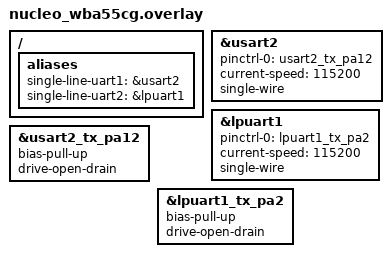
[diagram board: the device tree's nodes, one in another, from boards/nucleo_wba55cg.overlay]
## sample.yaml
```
sample:
  name: STM32 Single Wire UART sample
tests:
  sample.boards.stm32.uart.single_wire:
    platform_allow:
      - stm32f3_disco
      - nucleo_wba55cg
    tags:
      - drivers
      - uart
    harness: console
    harness_config:
      fixture: single_line_uart_loopback
      type: one_line
      regex:
        - "Received c"
```

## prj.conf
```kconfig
# SPDX-FileCopyrightText: Copyright The Zephyr Project Contributors
# SPDX-License-Identifier: Apache-2.0

# Nothing needed here
```

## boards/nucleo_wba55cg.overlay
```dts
/*
 * SPDX-License-Identifier: Apache-2.0
 *
 * Copyright (c) 2025 STMicroelectronics
 */

&usart2 {
	pinctrl-0 = <&usart2_tx_pa12>;
	current-speed = <115200>;
	single-wire;
	status = "okay";
};

&lpuart1 {
	pinctrl-0 = <&lpuart1_tx_pa2>;
	current-speed = <115200>;
	single-wire;
	status = "okay";
};

&usart2_tx_pa12 {
	bias-pull-up;
	drive-open-drain;
};

&lpuart1_tx_pa2 {
	bias-pull-up;
	drive-open-drain;
};

/ {
	aliases {
		single-line-uart1 = &usart2;
		single-line-uart2 = &lpuart1;
	};
};
```

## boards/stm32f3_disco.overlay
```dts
/*
 * Copyright (c) 2021 Jonathan Hahn
 *
 * SPDX-License-Identifier: Apache-2.0
 */

/ {
	aliases {
		single-line-uart1 = &usart2;
		single-line-uart2 = &uart4;
	};
};

&usart2 {
	pinctrl-0 = <&usart2_tx_pa2>;
	single-wire;
};

&uart4 {
	pinctrl-0 = <&uart4_tx_pc10>;
	single-wire;
};
```

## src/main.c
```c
/*
 * Copyright (c) 2021 Jonathan Hahn
 *
 * SPDX-License-Identifier: Apache-2.0
 */

#include <zephyr/kernel.h>
#include <zephyr/device.h>
#include <zephyr/devicetree.h>
#include <zephyr/drivers/uart.h>

#define UART_NODE1 DT_ALIAS(single_line_uart1)
#define UART_NODE2 DT_ALIAS(single_line_uart2)

const struct device *const sl_uart1 = DEVICE_DT_GET(UART_NODE1);
const struct device *const sl_uart2 = DEVICE_DT_GET(UART_NODE2);

int main(void)
{
	unsigned char recv;

	if (!device_is_ready(sl_uart1) || !device_is_ready(sl_uart2)) {
		printk("uart devices not ready\n");
		return 0;
	}

	while (true) {

		uart_poll_out(sl_uart1, 'c');

		/* give the uarts some time to get the data through */
		k_sleep(K_MSEC(50));

		int ret = uart_poll_in(sl_uart2, &recv);

		if (ret < 0) {
			printk("Receiving failed. Error: %d", ret);
		} else {
			printk("Received %c\n", recv);
		}

		k_sleep(K_MSEC(2000));
	}
	return 0;
}
```
